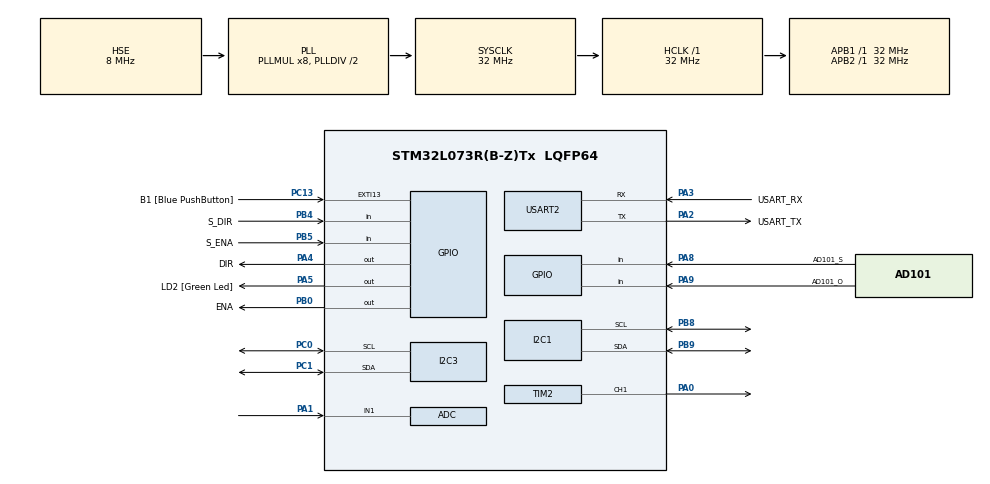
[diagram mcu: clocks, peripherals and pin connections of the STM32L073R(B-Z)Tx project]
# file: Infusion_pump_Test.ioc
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ADC.ContinuousConvMode=ENABLE
ADC.DMAContinuousRequests=ENABLE
ADC.DiscontinuousConvMode=DISABLE
ADC.SamplingTime=ADC_SAMPLETIME_19CYCLES_5
Dma.ADC.0.Direction=DMA_PERIPH_TO_MEMORY
Dma.ADC.0.Instance=DMA1_Channel1
Dma.ADC.0.MemDataAlignment=DMA_MDATAALIGN_WORD
Dma.ADC.0.MemInc=DMA_MINC_ENABLE
Dma.ADC.0.Mode=DMA_CIRCULAR
Dma.ADC.0.PeriphDataAlignment=DMA_PDATAALIGN_HALFWORD
Dma.ADC.0.PeriphInc=DMA_PINC_DISABLE
Dma.ADC.0.Priority=DMA_PRIORITY_LOW
Dma.Request0=ADC
I2C1.Timing=0x00707CBB
I2C3.Timing=0x00707CBB
Mcu.Family=STM32L0
Mcu.Name=STM32L073R(B-Z)Tx
Mcu.Package=LQFP64
NVIC.TIM2_IRQn=true\:0\:0\:false\:false\:true\:true\:true
PA0.Signal=S_TIM2_CH1
PA1.Mode=IN1
PA1.Signal=ADC_IN1
PA13.GPIO_Label=TMS
PA13.Mode=Serial_Wire
PA13.Signal=SYS_SWDIO
PA14.GPIO_Label=TCK
PA14.Mode=Serial_Wire
PA14.Signal=SYS_SWCLK
PA2.GPIO_Label=USART_TX
PA2.Mode=Asynchronous
PA2.Signal=USART2_TX
PA3.GPIO_Label=USART_RX
PA3.Mode=Asynchronous
PA3.Signal=USART2_RX
PA4.GPIO_Label=DIR
PA4.PinState=GPIO_PIN_RESET
PA4.Signal=GPIO_Output
PA5.GPIO_Label=LD2 [Green Led]
PA5.PinState=GPIO_PIN_RESET
PA5.Signal=GPIO_Output
PA8.GPIO_Label=AD101_S
PA8.Signal=GPIO_Input
PA9.GPIO_Label=AD101_O
PA9.Signal=GPIO_Input
PB0.GPIO_Label=ENA
PB0.PinState=GPIO_PIN_SET
PB0.Signal=GPIO_Output
PB4.GPIO_Label=S_DIR
PB4.GPIO_PuPd=GPIO_PULLUP
PB4.Signal=GPIO_Input
PB5.GPIO_Label=S_ENA
PB5.GPIO_PuPd=GPIO_PULLUP
PB5.Signal=GPIO_Input
PB8.GPIO_FM8=I2C_FASTMODEPLUS_PB8
PB8.Mode=I2C
PB8.Signal=I2C1_SCL
PB9.GPIO_FM9=I2C_FASTMODEPLUS_PB9
PB9.Mode=I2C
PB9.Signal=I2C1_SDA
PC0.Mode=I2C
PC0.Signal=I2C3_SCL
PC1.Mode=I2C
PC1.Signal=I2C3_SDA
PC13.GPIO_Label=B1 [Blue PushButton]
PC13.GPIO_ModeDefaultEXTI=GPIO_MODE_IT_FALLING
PC13.Signal=GPXTI13
PC14-OSC32_IN.Mode=LSE-External-Oscillator
PC14-OSC32_IN.Signal=RCC_OSC32_IN
PC15-OSC32_OUT.Mode=LSE-External-Oscillator
PC15-OSC32_OUT.Signal=RCC_OSC32_OUT
PH0-OSC_IN.GPIO_Label=MCO
PH0-OSC_IN.Mode=HSE-External-Clock-Source
PH0-OSC_IN.Signal=RCC_OSC_IN
ProjectManager.HeapSize=0x200
ProjectManager.StackSize=0x400
ProjectManager.TargetToolchain=STM32CubeIDE
RCC.AHBFreq_Value=32000000
RCC.APB1Freq_Value=32000000
RCC.APB1TimFreq_Value=32000000
RCC.APB2Freq_Value=32000000
RCC.APB2TimFreq_Value=32000000
RCC.HCLKFreq_Value=32000000
RCC.HSE_VALUE=8000000
RCC.HSI16_VALUE=16000000
RCC.HSI48_VALUE=48000000
RCC.HSI_VALUE=16000000
RCC.MSI_VALUE=2097000
RCC.PLLMUL=RCC_PLLMUL_8
RCC.PLLSourceVirtual=RCC_PLLSOURCE_HSE
RCC.SYSCLKFreq_VALUE=32000000
RCC.SYSCLKSource=RCC_SYSCLKSOURCE_PLLCLK
RCC.VCOOutputFreq_Value=64000000
SH.S_TIM2_CH1.0=TIM2_CH1,PWM Generation1 CH1
TIM2.Channel-PWM\ Generation1\ CH1=TIM_CHANNEL_1
TIM2.OCFastMode_PWM-PWM\ Generation1\ CH1=TIM_OCFAST_ENABLE
TIM2.Period=50000
TIM2.Prescaler=1
TIM2.Pulse-PWM\ Generation1\ CH1=25000
USART2.VirtualMode-Asynchronous=VM_ASYNC
board=NUCLEO-L073RZ

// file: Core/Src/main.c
/* USER CODE BEGIN Header */
/**
  ******************************************************************************
  * @file           : main.c
  * @brief          : Main program body
  ******************************************************************************
  * @attention
  *
  * <h2><center>&copy; Copyright (c) 2021 STMicroelectronics.
  * All rights reserved.</center></h2>
  *
  * This software component is licensed by ST under BSD 3-Clause license,
  * the "License"; You may not use this file except in compliance with the
  * License. You may obtain a copy of the License at:
  *                        opensource.org/licenses/BSD-3-Clause
  *
  ******************************************************************************
  */
/* USER CODE END Header */
#include "main.h"
#include "adc.h"
#include "dma.h"
#include "i2c.h"
#include "tim.h"
#include "usart.h"
#include "gpio.h"

/* USER CODE BEGIN Includes */
#include "Operation.h"
/* USER CODE END Includes */

/* USER CODE BEGIN PV */
uint8_t Com_Header[]="\r\nSec\tAD101 Test\tAD101 Status\tForce1\tTemp1\tForce2\tTemp2";

//uint8_t Com_Header[]="\r\nTest Sensor (Infusion Pump) By Natthapoom.T";
/* USER CODE END PV */

void SystemClock_Config(void);

int main(void)
{

  /* MCU Configuration--------------------------------------------------------*/

  /* Reset of all peripherals, Initializes the Flash interface and the Systick. */
  HAL_Init();

  /* Configure the system clock */
  SystemClock_Config();

  /* Initialize all configured peripherals */
  MX_GPIO_Init();
  MX_DMA_Init();
  MX_ADC_Init();
  MX_TIM2_Init();
  MX_USART2_UART_Init();
  MX_I2C1_Init();
  MX_I2C3_Init();
  /* USER CODE BEGIN 2 */
  HAL_TIM_PWM_Start_IT(&htim2, TIM_CHANNEL_1);

  HAL_ADC_Start_DMA(&hadc,(uint32_t *)aADCxConvertedData, ADC_CONVERTED_DATA_BUFFER_SIZE);
  HAL_UART_Transmit(&huart2, Com_Header, sizeof(Com_Header), 10000);

  /* USER CODE END 2 */

  /* Infinite loop */
  while (1)
  {

    /* USER CODE BEGIN 3 */
	  operation();

  }
  /* USER CODE END 3 */
}

void SystemClock_Config(void)
{
  RCC_OscInitTypeDef RCC_OscInitStruct = {0};
  RCC_ClkInitTypeDef RCC_ClkInitStruct = {0};
  RCC_PeriphCLKInitTypeDef PeriphClkInit = {0};

  /** Configure the main internal regulator output voltage
  */
  __HAL_PWR_VOLTAGESCALING_CONFIG(PWR_REGULATOR_VOLTAGE_SCALE1);
  /** Initializes the RCC Oscillators according to the specified parameters
  * in the RCC_OscInitTypeDef structure.
  */
  RCC_OscInitStruct.OscillatorType = RCC_OSCILLATORTYPE_HSE;
  RCC_OscInitStruct.HSEState = RCC_HSE_BYPASS;
  RCC_OscInitStruct.PLL.PLLState = RCC_PLL_ON;
  RCC_OscInitStruct.PLL.PLLSource = RCC_PLLSOURCE_HSE;
  RCC_OscInitStruct.PLL.PLLMUL = RCC_PLLMUL_8;
  RCC_OscInitStruct.PLL.PLLDIV = RCC_PLLDIV_2;
  if (HAL_RCC_OscConfig(&RCC_OscInitStruct) != HAL_OK)
  {
    Error_Handler();
  }
  /** Initializes the CPU, AHB and APB buses clocks
  */
  RCC_ClkInitStruct.ClockType = RCC_CLOCKTYPE_HCLK|RCC_CLOCKTYPE_SYSCLK
                              |RCC_CLOCKTYPE_PCLK1|RCC_CLOCKTYPE_PCLK2;
  RCC_ClkInitStruct.SYSCLKSource = RCC_SYSCLKSOURCE_PLLCLK;
  RCC_ClkInitStruct.AHBCLKDivider = RCC_SYSCLK_DIV1;
  RCC_ClkInitStruct.APB1CLKDivider = RCC_HCLK_DIV1;
  RCC_ClkInitStruct.APB2CLKDivider = RCC_HCLK_DIV1;

  if (HAL_RCC_ClockConfig(&RCC_ClkInitStruct, FLASH_LATENCY_1) != HAL_OK)
  {
    Error_Handler();
  }
  PeriphClkInit.PeriphClockSelection = RCC_PERIPHCLK_USART2|RCC_PERIPHCLK_I2C1
                              |RCC_PERIPHCLK_I2C3;
  PeriphClkInit.Usart2ClockSelection = RCC_USART2CLKSOURCE_PCLK1;
  PeriphClkInit.I2c1ClockSelection = RCC_I2C1CLKSOURCE_PCLK1;
  PeriphClkInit.I2c3ClockSelection = RCC_I2C3CLKSOURCE_PCLK1;
  if (HAL_RCCEx_PeriphCLKConfig(&PeriphClkInit) != HAL_OK)
  {
    Error_Handler();
  }
}

void Error_Handler(void)
{
  __disable_irq();
  while (1)
  {
  }
}

/************************ (C) COPYRIGHT STMicroelectronics *****END OF FILE****/
